# STM32N655 register map
File version: 1.0
CPU: CM55 r0p1, little endian, no MPU, FPU, vendor SysTick, 8 interrupt priority bits
Registers are 32-bit, read-write, reset 0x0 unless marked. A register's access mark holds for its fields unless they carry their own. Offsets are from the block's base; [hi:lo] are bit positions; {n}, {i} and the like mark numbered series.

## GPIOA — General-purpose I/Os
Base 0x46020000
Same registers: GPIOA_S 0x56020000
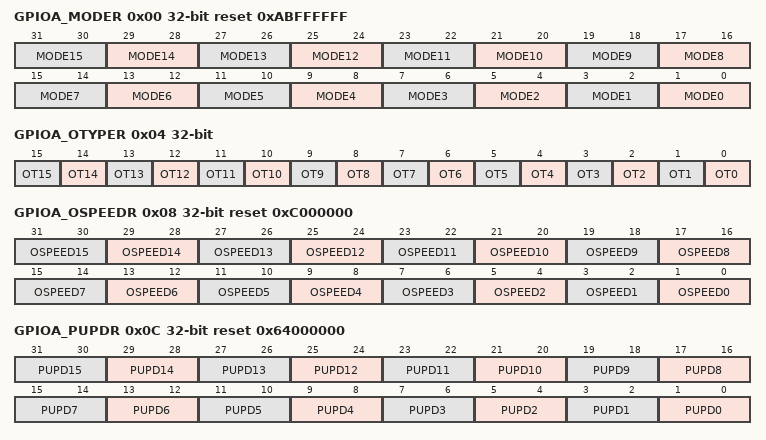
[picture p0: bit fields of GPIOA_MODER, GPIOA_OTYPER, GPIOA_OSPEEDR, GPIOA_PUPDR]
0x00 GPIOA_MODER reset 0xABFFFFFF — GPIO port A mode register
  [all] fields
    0=General-purpose input mode; 1=General-purpose output mode; 2=Alternate function mode (refer to device datasheet for available options); 3=Analog mode (reset state)
  [2n+1:2n] MODE{n} (n=0..15) — Port x configuration I/O pin y
0x04 GPIOA_OTYPER — GPIO port A output type register
  [all] fields
    0=Output push-pull (reset state); 1=Output open-drain
  [n] OT{n} (n=0..15) — Port x configuration I/O pin y
0x08 GPIOA_OSPEEDR reset 0xC000000 — GPIO port A output speed register
  [all] fields
    0=Low speed; 1=Medium speed; 2=High speed; 3=Very high speed
  [2n+1:2n] OSPEED{n} (n=0..15) — Port x configuration I/O pin y
0x0C GPIOA_PUPDR reset 0x64000000 — GPIO port A pull-up/pull-down register
  [all] fields
    0=No pull-up, pull-down; 1=Pull-up; 2=Pull-down
  [2n+1:2n] PUPD{n} (n=0..15) — Port x configuration I/O pin y
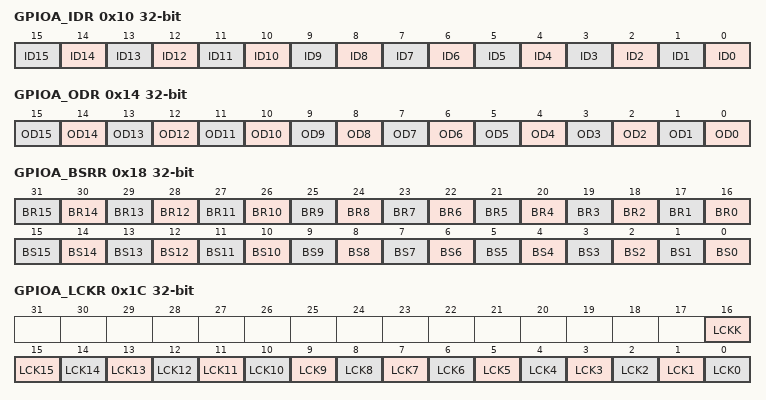
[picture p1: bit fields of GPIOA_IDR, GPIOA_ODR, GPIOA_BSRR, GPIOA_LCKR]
0x10 GPIOA_IDR ro (reset mask 0xFFFF0000) — GPIO port A input data register
  [n] ID{n} (n=0..15) — Port x input data I/O pin y
0x14 GPIOA_ODR — GPIO port A output data register
  [n] OD{n} (n=0..15) — Port x output data I/O pin y
0x18 GPIOA_BSRR wo — GPIO port A bit set/reset register
  [n+16] BR{n} (n=0..15) — Port x reset I/O pin y
    0=No action on the corresponding ODy bit; 1=Resets the corresponding ODy bit
  [n] BS{n} (n=0..15) — Port x set I/O pin y
    0=No action on the corresponding ODx bit; 1=Sets the corresponding ODx bit
0x1C GPIOA_LCKR — GPIO port A configuration lock register
  [16] LCKK — Lock key
    0=Port configuration lock key not active; 1=Port configuration lock key active. The GPIOx_LCKR register is locked until the next MCU reset or peripheral reset.
  [n] LCK{n} (n=0..15) — Port x lock I/O pin y
    0=Port configuration not locked; 1=Port configuration locked
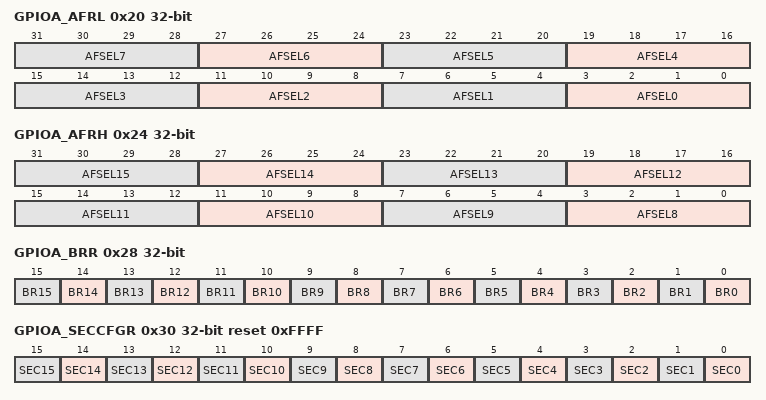
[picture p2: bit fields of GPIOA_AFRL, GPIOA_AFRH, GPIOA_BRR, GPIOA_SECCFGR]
0x20 GPIOA_AFRL — GPIO port A alternate function low register
  [all] fields
    {v}=AF{v} (v=0..15)
  [4n+3:4n] AFSEL{n} (n=0..7) — Alternate function selection for port x I/O pin y
0x24 GPIOA_AFRH — GPIO port A alternate function high register
  [4n-29:4n-32] AFSEL{n} (n=8..15) — Alternate function selection for port x I/O pin y
0x28 GPIOA_BRR wo — GPIO port A bit reset register
  [all] fields
    0=No action on the corresponding ODx bit; 1=Reset the corresponding ODx bit
  [n] BR{n} (n=0..15) — Port x reset IO pin y
0x30 GPIOA_SECCFGR reset 0xFFFF — GPIO port A secure configuration register
  [all] fields
    0=The I/O pin y is non-secure. Secure access is also possible.; 1=The I/O pin y is secure (see Table 70 for all corresponding secure bits)
  [n] SEC{n} (n=0..15) — I/O pin y of Port x security configuration
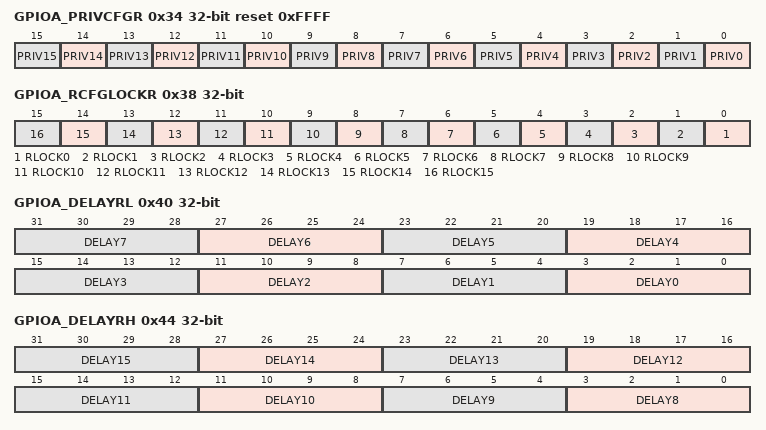
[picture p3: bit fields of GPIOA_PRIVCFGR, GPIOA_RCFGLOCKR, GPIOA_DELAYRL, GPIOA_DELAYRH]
0x34 GPIOA_PRIVCFGR reset 0xFFFF — GPIO port A privileged configuration register
  [all] fields
    0=The I/O pin y is unprivileged. Privileged access is also possible.; 1=The I/O pin y is privileged only (see Table 70 for all corresponding protected bits)
  [n] PRIV{n} (n=0..15) — I/O pin y of Port x privilege configuration
0x38 GPIOA_RCFGLOCKR — GPIO port A resource configuration lock register
  [all] fields
    0=SECy in GPIOx_SECCFGR and PRIVy in GPIOx_PRIVCFGR are writable; 1=Writes to SECy in GPIOx_SECCFGR and PRIVy in GPIOx_PRIVCFGR are ignored
  [n] RLOCK{n} (n=0..15) — I/O pin y of port x resource lock
0x40 GPIOA_DELAYRL — GPIO port A delay low register
  [all] fields
    0=No delay; 1=Delay 0.3 ns; 2=Delay 0.5 ns; 3=Delay 0.75 ns; 4=Delay 1.0 ns; 5=Delay 1.25 ns; 6=Delay 1.5 ns; 7=Delay 1.75 ns; 8=Delay 2.0 ns; 9=Delay 2.25 ns; 10=Delay 2.5 ns; 11=Delay 2.75 ns; 12=Delay 3.0 ns; 13=Delay 3.25 ns
  [4n+3:4n] DELAY{n} (n=0..7) — Port x IO pin y delay setup
0x44 GPIOA_DELAYRH — GPIO port A delay high register
  [4n-29:4n-32] DELAY{n} (n=8..15) — Port x I/O pin y delay setup
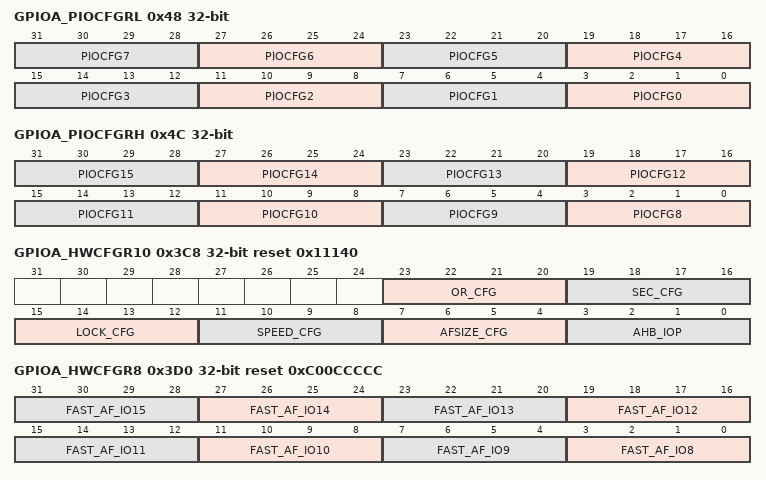
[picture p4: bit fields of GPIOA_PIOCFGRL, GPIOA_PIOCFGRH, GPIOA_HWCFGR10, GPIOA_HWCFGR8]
0x48 GPIOA_PIOCFGRL — GPIO port A PIO control low register
  [all] fields
    0=Input and output data are not synchronized or retimed on clock edges; 1=Input and output data are retimed to either rising or falling clock edge depending on PIOCFG[2] value (cfg_invertclk)
  [4n+3:4n] PIOCFG{n} (n=0..7) — Port x I/O pin y configuration
0x4C GPIOA_PIOCFGRH — GPIO port A PIO control high register
  [4n-29:4n-32] PIOCFG{n} (n=8..15) — Port x I/O pin y configuration
0x3C8 GPIOA_HWCFGR10 ro reset 0x11140 — GPIO port A hardware configuration register 10
  [23:20] OR_CFG — Option register configuration
    0=Non-active; 1=Active
  [19:16] SEC_CFG — Security activation
    0=Non-active; 1=Active
  [15:12] LOCK_CFG — Lock mechanism activation
    0=Non-active; 1=Active
  [11:8] SPEED_CFG — Number of speed lines for each I/O
    0=One line; 1=Two lines
  [7:4] AFSIZE_CFG — Number of AF available for each I/O (accepted value: 1 to 4)
    1=One AF/IO
  [3:0] AHB_IOP — Bus interface selection
    0=AHB; 1=IOP
0x3CC GPIOA_HWCFGR9 ro reset 0xFFFF — GPIO port A hardware configuration register 9
  [15:0] EN_IO — Presence granularity, each bit indicate the I/O presence
    0=I/O not present; 1=I/O present
0x3D0 GPIOA_HWCFGR8 ro reset 0xC00CCCCC — GPIO port A hardware configuration register 8
  [4n-29:4n-32] FAST_AF_IO{n} (n=8..15) — Indicate which is the fastest AF for I/Oy (0 to F)
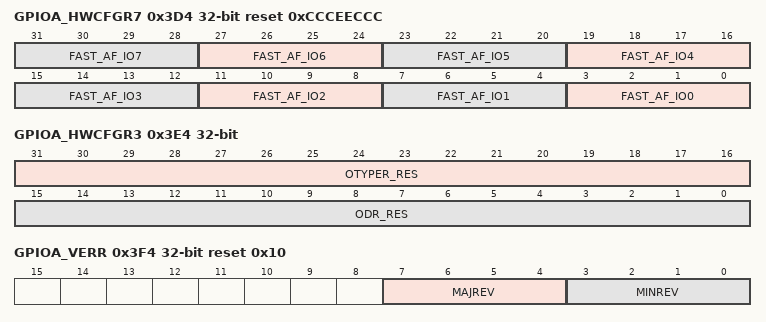
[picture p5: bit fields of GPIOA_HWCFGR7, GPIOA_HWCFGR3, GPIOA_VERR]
0x3D4 GPIOA_HWCFGR7 ro reset 0xCCCEECCC — GPIO port A hardware configuration register 7
  [4n+3:4n] FAST_AF_IO{n} (n=0..7) — Indicate which is the fastest AF for I/Oy (0 to F)
0x3D8 GPIOA_HWCFGR6 ro reset 0xABFFFFFF — GPIO port A hardware configuration register 6
  [31:0] MODER_RES — MODER register reset value
0x3DC GPIOA_HWCFGR5 ro reset 0x64000000 — GPIO port A hardware configuration register 5
  [31:0] PUPDR_RES — Pull-up/pull-down register reset value
0x3E0 GPIOA_HWCFGR4 ro reset 0xC000000 — GPIO port A hardware configuration register 4
  [31:0] OSPEED_RES — OSPEED register reset value
0x3E4 GPIOA_HWCFGR3 ro — GPIO port A hardware configuration register 3
  [31:16] OTYPER_RES — Output type register reset value
  [15:0] ODR_RES — Output data register reset value
0x3E8 GPIOA_HWCFGR2 ro — GPIO port A hardware configuration register 2
  [31:0] AFRL_RES — AF register low reset value
0x3EC GPIOA_HWCFGR1 ro — GPIO port A hardware configuration register 1
  [31:0] AFRH_RES — AF register high reset value
0x3F0 GPIOA_HWCFGR0 ro — GPIO port A hardware configuration register 0
  [15:0] OR_RES — Option register reset value
0x3F4 GPIOA_VERR ro reset 0x10 — GPIO port A version register
  [7:4] MAJREV — GPIO major revision
  [3:0] MINREV — GPIO minor revision
0x3F8 GPIOA_IPIDR ro reset 0xF0004 — GPIO port A identification register
  [31:0] IPID — GPIO identifier
0x3FC GPIOA_SIDR ro reset 0xA3C5DD01 — GPIO port A size identification register
  [31:0] SID — Size of the memory region allocated to GPIO registers
